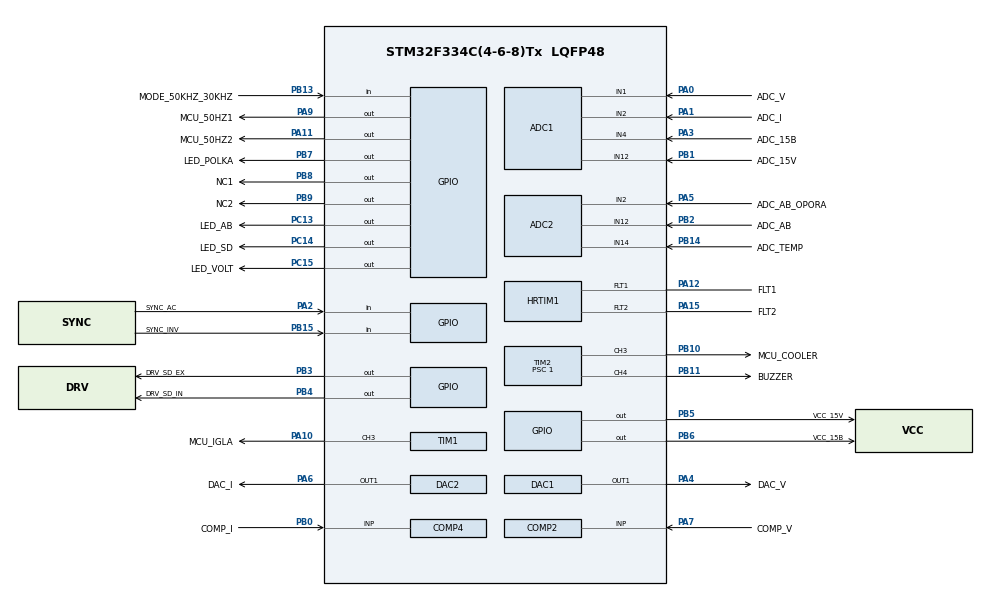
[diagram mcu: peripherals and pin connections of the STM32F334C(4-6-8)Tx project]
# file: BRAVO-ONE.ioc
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ADC1.AWD1HighThreshold=2500
ADC1.AWD1ITMode=ENABLE
ADC1.AWD1LowThreshold=1500
ADC1.Channel-3\#ChannelRegularConversion=ADC_CHANNEL_4
ADC1.Channel-4\#ChannelRegularConversion=ADC_CHANNEL_12
ADC1.ContinuousConvMode=ENABLE
ADC1.DMAContinuousRequests=ENABLE
ADC1.EOCSelection=ADC_EOC_SEQ_CONV
ADC1.EnableAnalogWatchDog1=true
ADC1.EnableRegularConversion=ENABLE
ADC1.ExternalTrigInjecConv=ADC_EXTERNALTRIGINJECCONV_HRTIM_TRG2
ADC1.ExternalTrigInjecConvEdge=ADC_EXTERNALTRIGINJECCONV_EDGE_RISINGFALLING
ADC1.InjNumberOfConversion=2
ADC1.InjectedChannel-1\#ChannelInjectedConversion=ADC_CHANNEL_1
ADC1.InjectedChannel-2\#ChannelInjectedConversion=ADC_CHANNEL_2
ADC1.InjectedConvMode=None
ADC1.InjectedOffset-1\#ChannelInjectedConversion=0
ADC1.InjectedOffset-2\#ChannelInjectedConversion=0
ADC1.InjectedOffsetNumber-1\#ChannelInjectedConversion=ADC_OFFSET_NONE
ADC1.InjectedOffsetNumber-2\#ChannelInjectedConversion=ADC_OFFSET_NONE
ADC1.InjectedRank-1\#ChannelInjectedConversion=1
ADC1.InjectedRank-2\#ChannelInjectedConversion=2
ADC1.InjectedSamplingTime-1\#ChannelInjectedConversion=ADC_SAMPLETIME_61CYCLES_5
ADC1.InjectedSamplingTime-2\#ChannelInjectedConversion=ADC_SAMPLETIME_61CYCLES_5
ADC1.NbrOfConversion=2
ADC1.NbrOfConversionFlag=1
ADC1.Offset-3\#ChannelRegularConversion=0
ADC1.Offset-4\#ChannelRegularConversion=0
ADC1.OffsetNumber-3\#ChannelRegularConversion=ADC_OFFSET_NONE
ADC1.OffsetNumber-4\#ChannelRegularConversion=ADC_OFFSET_NONE
ADC1.QueueInjectedContext=ENABLE
ADC1.Rank-3\#ChannelRegularConversion=1
ADC1.Rank-4\#ChannelRegularConversion=2
ADC1.SamplingTime-3\#ChannelRegularConversion=ADC_SAMPLETIME_601CYCLES_5
ADC1.SamplingTime-4\#ChannelRegularConversion=ADC_SAMPLETIME_601CYCLES_5
ADC1.WatchdogMode=ADC_ANALOGWATCHDOG_ALL_REG
ADC1.master=1
ADC2.AWD1HighThreshold=2500
ADC2.AWD1ITMode=ENABLE
ADC2.AWD1LowThreshold=1500
ADC2.Channel-0\#ChannelRegularConversion=ADC_CHANNEL_14
ADC2.Channel-1\#ChannelRegularConversion=ADC_CHANNEL_12
ADC2.Channel-2\#ChannelRegularConversion=ADC_CHANNEL_2
ADC2.ContinuousConvMode=ENABLE
ADC2.DMAContinuousRequests=ENABLE
ADC2.EOCSelection=ADC_EOC_SEQ_CONV
ADC2.EnableAnalogWatchDog1=true
ADC2.EnableInjectedConversion=DISABLE
ADC2.NbrOfConversion=3
ADC2.NbrOfConversionFlag=1
ADC2.Offset-0\#ChannelRegularConversion=0
ADC2.Offset-1\#ChannelRegularConversion=0
ADC2.Offset-2\#ChannelRegularConversion=0
ADC2.OffsetNumber-0\#ChannelRegularConversion=ADC_OFFSET_NONE
ADC2.OffsetNumber-1\#ChannelRegularConversion=ADC_OFFSET_NONE
ADC2.OffsetNumber-2\#ChannelRegularConversion=ADC_OFFSET_NONE
ADC2.Rank-0\#ChannelRegularConversion=1
ADC2.Rank-1\#ChannelRegularConversion=2
ADC2.Rank-2\#ChannelRegularConversion=3
ADC2.SamplingTime-0\#ChannelRegularConversion=ADC_SAMPLETIME_601CYCLES_5
ADC2.SamplingTime-1\#ChannelRegularConversion=ADC_SAMPLETIME_601CYCLES_5
ADC2.SamplingTime-2\#ChannelRegularConversion=ADC_SAMPLETIME_601CYCLES_5
ADC2.WatchdogChannel=ADC_CHANNEL_12
COMP2.InvertingInput=COMP_INVERTINGINPUT_DAC1_CH1
COMP2.TriggerMode=COMP_TRIGGERMODE_IT_RISING_FALLING
COMP4.InvertingInput=COMP_INVERTINGINPUT_DAC2_CH1
COMP4.TriggerMode=COMP_TRIGGERMODE_IT_RISING_FALLING
DAC1.DAC_Trigger=DAC_TRIGGER_HRTIM1_DACTRG1
DAC1.TriangleAmplitude=DAC_TRIANGLEAMPLITUDE_4095
DAC1.WaveGeneration=TriangleWaveGeneration
DAC2.DAC_Trigger=DAC_TRIGGER_HRTIM1_DACTRG3
Dma.ADC1.0.Direction=DMA_PERIPH_TO_MEMORY
Dma.ADC1.0.Instance=DMA1_Channel1
Dma.ADC1.0.MemDataAlignment=DMA_MDATAALIGN_HALFWORD
Dma.ADC1.0.MemInc=DMA_MINC_ENABLE
Dma.ADC1.0.Mode=DMA_CIRCULAR
Dma.ADC1.0.PeriphDataAlignment=DMA_PDATAALIGN_HALFWORD
Dma.ADC1.0.PeriphInc=DMA_PINC_DISABLE
Dma.ADC1.0.Priority=DMA_PRIORITY_MEDIUM
Dma.ADC2.1.Direction=DMA_PERIPH_TO_MEMORY
Dma.ADC2.1.Instance=DMA1_Channel4
Dma.ADC2.1.MemDataAlignment=DMA_MDATAALIGN_HALFWORD
Dma.ADC2.1.MemInc=DMA_MINC_ENABLE
Dma.ADC2.1.Mode=DMA_CIRCULAR
Dma.ADC2.1.PeriphDataAlignment=DMA_PDATAALIGN_HALFWORD
Dma.ADC2.1.PeriphInc=DMA_PINC_DISABLE
Dma.ADC2.1.Priority=DMA_PRIORITY_LOW
Dma.DAC1_CH1.2.Direction=DMA_MEMORY_TO_PERIPH
Dma.DAC1_CH1.2.Instance=DMA1_Channel3
Dma.DAC1_CH1.2.MemDataAlignment=DMA_MDATAALIGN_HALFWORD
Dma.DAC1_CH1.2.MemInc=DMA_MINC_ENABLE
Dma.DAC1_CH1.2.Mode=DMA_CIRCULAR
Dma.DAC1_CH1.2.PeriphDataAlignment=DMA_PDATAALIGN_HALFWORD
Dma.DAC1_CH1.2.PeriphInc=DMA_PINC_DISABLE
Dma.DAC1_CH1.2.Priority=DMA_PRIORITY_VERY_HIGH
Dma.DAC2_CH1.3.Direction=DMA_MEMORY_TO_PERIPH
Dma.DAC2_CH1.3.Instance=DMA1_Channel5
Dma.DAC2_CH1.3.MemDataAlignment=DMA_MDATAALIGN_HALFWORD
Dma.DAC2_CH1.3.MemInc=DMA_MINC_ENABLE
Dma.DAC2_CH1.3.Mode=DMA_CIRCULAR
Dma.DAC2_CH1.3.PeriphDataAlignment=DMA_PDATAALIGN_HALFWORD
Dma.DAC2_CH1.3.PeriphInc=DMA_PINC_DISABLE
Dma.DAC2_CH1.3.Priority=DMA_PRIORITY_HIGH
Dma.Request0=ADC1
Dma.Request1=ADC2
Dma.Request2=DAC1_CH1
Dma.Request3=DAC2_CH1
HRTIM1.ADCTrigger2_Source1=HRTIM_ADCTRIGGEREVENT24_MASTER_CMP2
HRTIM1.ADCTrigger2_Source2=HRTIM_ADCTRIGGEREVENT24_MASTER_CMP4
HRTIM1.ADCTrigger_Id1=__NULL
HRTIM1.ADCTrigger_Id2=HRTIM_ADCTRIGGER_2
HRTIM1.BurstDMAconfig-MasterTimer=__NULL
HRTIM1.CompareUnit1-MasterTimer=HRTIM_COMPAREUNIT_1
HRTIM1.CompareUnit2-MasterTimer=HRTIM_COMPAREUNIT_2
HRTIM1.CompareUnit3-MasterTimer=HRTIM_COMPAREUNIT_3
HRTIM1.CompareUnit4-MasterTimer=HRTIM_COMPAREUNIT_4
HRTIM1.CompareValue1-MasterTimer=3400
HRTIM1.CompareValue2-MasterTimer=10200
HRTIM1.CompareValue3-MasterTimer=28400
HRTIM1.CompareValue4-MasterTimer=35200
HRTIM1.DACSynchro-MasterTimer=HRTIM_DACSYNC_NONE
HRTIM1.Enable=HRTIM_BURSTMODECTL_DISABLED
HRTIM1.Event_EEV1=HRTIM_EVENT_1
HRTIM1.Event_EEV2=HRTIM_EVENT_2
HRTIM1.Event_EEV3=__NULL
HRTIM1.Event_EEV4=__NULL
HRTIM1.Event_EEV5=__NULL
HRTIM1.Event_EEV6=__NULL
HRTIM1.Event_EEV7=__NULL
HRTIM1.FastMode_EEV1=HRTIM_EVENTFASTMODE_ENABLE
HRTIM1.FastMode_EEV2=HRTIM_EVENTFASTMODE_ENABLE
HRTIM1.FaultEnable_Source1-No_output_TE=HRTIM_TIMFAULTENABLE_FAULT1
HRTIM1.FaultEnable_Source2-No_output_TE=HRTIM_TIMFAULTENABLE_FAULT2
HRTIM1.Filter_FaultLine1=HRTIM_FAULTFILTER_15
HRTIM1.Filter_FaultLine2=HRTIM_FAULTFILTER_15
HRTIM1.HRTIMInterruptResquests1=HRTIM_IT_FLT1
HRTIM1.HRTIMInterruptResquests2=HRTIM_IT_FLT2
HRTIM1.HRTIMInterruptResquests3=HRTIM_IT_SYSFLT
HRTIM1.InterruptRequests1-No_output_TE=HRTIM_TIM_IT_REP
HRTIM1.InterruptRequests1_Master=HRTIM_MASTER_IT_MREP
HRTIM1.ModeTimeBase-No_output_TE=HRTIM_MODE_SINGLESHOT_RETRIGGERABLE
HRTIM1.NumberADCTriggerSource2=2
HRTIM1.NumberDMARequests_Master=0
HRTIM1.NumberFaultEnable-No_output_TE=2
HRTIM1.NumberInterruptRequests-No_output_TE=1
HRTIM1.NumberInterruptRequests_Master-MasterTimer=1
HRTIM1.NumberResetTrigger-No_output_TE=1
HRTIM1.NumberUpdateTrigger-No_output_TE=1
HRTIM1.Periode_MASTER=50000
HRTIM1.Periode_TE=50000
HRTIM1.PreloadEnable-MasterTimer=HRTIM_PRELOAD_ENABLED
HRTIM1.PreloadEnable-No_output_TE=HRTIM_PRELOAD_ENABLED
HRTIM1.PrescalerRatio_MASTER=HRTIM_PRESCALERRATIO_MUL16
HRTIM1.PrescalerRatio_TE=HRTIM_PRESCALERRATIO_MUL16
HRTIM1.RepetitionCounter-MasterTimer=230
HRTIM1.RepetitionCounter-No_output_TE=227
HRTIM1.RepetitionUpdate-MasterTimer=HRTIM_UPDATEONREPETITION_ENABLED
HRTIM1.ResetTrigger1-No_output_TE=HRTIM_TIMRESETTRIGGER_UPDATE
HRTIM1.Source_EEV1=HRTIM_EVENTSRC_2
HRTIM1.UpdateTrigger1-No_output_TE=HRTIM_TIMUPDATETRIGGER_MASTER
IWDG.Prescaler=IWDG_PRESCALER_256
Mcu.Family=STM32F3
Mcu.Name=STM32F334C(4-6-8)Tx
Mcu.Package=LQFP48
NVIC.ADC1_2_IRQn=true\:0\:2\:true\:false\:true\:true\:true
NVIC.COMP2_IRQn=true\:0\:0\:false\:false\:true\:false\:true
NVIC.COMP4_6_IRQn=true\:0\:0\:false\:false\:true\:false\:true
NVIC.DMA1_Channel1_IRQn=true\:0\:1\:true\:false\:true\:false\:true
NVIC.DMA1_Channel3_IRQn=true\:0\:1\:true\:false\:true\:false\:true
NVIC.DMA1_Channel4_IRQn=true\:0\:1\:true\:false\:true\:false\:true
NVIC.DMA1_Channel5_IRQn=true\:0\:1\:true\:false\:true\:false\:true
NVIC.HRTIM1_FLT_IRQn=true\:0\:0\:false\:false\:true\:true\:true
NVIC.HRTIM1_Master_IRQn=true\:0\:0\:false\:false\:true\:true\:true
NVIC.HRTIM1_TIME_IRQn=true\:0\:0\:false\:false\:true\:true\:true
NVIC.PVD_IRQn=true\:0\:2\:true\:false\:true\:true\:true
NVIC.PriorityGroup=NVIC_PRIORITYGROUP_2
NVIC.TIM1_BRK_TIM15_IRQn=true\:3\:0\:true\:false\:true\:true\:true
NVIC.TIM1_TRG_COM_TIM17_IRQn=true\:3\:0\:true\:false\:true\:true\:true
NVIC.TIM1_UP_TIM16_IRQn=true\:3\:0\:true\:false\:true\:true\:true
NVIC.TIM3_IRQn=true\:3\:0\:true\:false\:true\:true\:true
NVIC.TIM6_DAC1_IRQn=true\:3\:0\:true\:false\:true\:true\:true
NVIC.TIM7_DAC2_IRQn=true\:3\:0\:true\:false\:true\:true\:true
PA0.GPIO_Label=ADC_V
PA0.Mode=IN1-Single-Ended
PA0.Signal=ADC1_IN1
PA1.GPIO_Label=ADC_I
PA1.Mode=IN2-Single-Ended
PA1.Signal=ADC1_IN2
PA10.GPIO_Label=MCU_IGLA
PA10.GPIO_Speed=GPIO_SPEED_FREQ_HIGH
PA10.Signal=S_TIM1_CH3
PA11.GPIO_Label=MCU_50HZ2
PA11.GPIO_Speed=GPIO_SPEED_FREQ_HIGH
PA11.Signal=GPIO_Output
PA12.GPIO_Label=FLT1
PA12.GPIO_Speed=GPIO_SPEED_FREQ_HIGH
PA12.Mode=Fault_Enable1
PA12.Signal=HRTIM1_FLT1
PA13.GPIO_Label=DIO
PA13.Mode=Serial_Wire
PA13.Signal=SYS_JTMS-SWDIO
PA14.GPIO_Label=CLK
PA14.Mode=Serial_Wire
PA14.Signal=SYS_JTCK-SWCLK
PA15.GPIO_Label=FLT2
PA15.GPIO_Speed=GPIO_SPEED_FREQ_HIGH
PA15.Mode=Fault_Enable2
PA15.Signal=HRTIM1_FLT2
PA2.GPIO_Label=SYNC_AC
PA2.Signal=GPIO_Input
PA3.GPIO_Label=ADC_15B
PA3.Mode=IN4-Single-Ended
PA3.Signal=ADC1_IN4
PA4.GPIO_Label=DAC_V
PA4.Signal=COMP_DAC11_group
PA5.GPIO_Label=ADC_AB_OPORA
PA5.Mode=IN2-Single-Ended
PA5.Signal=ADC2_IN2
PA6.GPIO_Label=DAC_I
PA6.Signal=COMP_DAC21_group
PA7.GPIO_Label=COMP_V
PA7.Mode=INP
PA7.Signal=COMP2_INP
PA8.GPIO_Label=IN1
PA8.Signal=HRTIM1_CHA1
PA9.GPIO_Label=MCU_50HZ1
PA9.GPIO_Speed=GPIO_SPEED_FREQ_HIGH
PA9.Signal=GPIO_Output
PB0.GPIO_Label=COMP_I
PB0.Mode=INP
PB0.Signal=COMP4_INP
PB1.GPIO_Label=ADC_15V
PB1.Mode=IN12-Single-Ended
PB1.Signal=ADC1_IN12
PB10.GPIO_Label=MCU_COOLER
PB10.GPIO_Speed=GPIO_SPEED_FREQ_HIGH
PB10.Signal=S_TIM2_CH3
PB11.GPIO_Label=BUZZER
PB11.GPIO_Speed=GPIO_SPEED_FREQ_HIGH
PB11.Signal=S_TIM2_CH4
PB12.GPIO_Label=IN2
PB12.Signal=HRTIM1_CHC1
PB13.GPIO_Label=MODE_50KHZ_30KHZ
PB13.Signal=GPIO_Input
PB14.GPIO_Label=ADC_TEMP
PB14.Mode=IN14-Single-Ended
PB14.Signal=ADC2_IN14
PB15.GPIO_Label=SYNC_INV
PB15.Signal=GPIO_Input
PB2.GPIO_Label=ADC_AB
PB2.Mode=IN12-Single-Ended
PB2.Signal=ADC2_IN12
PB3.GPIO_Label=DRV_SD_EX
PB3.GPIO_Speed=GPIO_SPEED_FREQ_HIGH
PB3.Signal=GPIO_Output
PB4.GPIO_Label=DRV_SD_IN
PB4.GPIO_Speed=GPIO_SPEED_FREQ_HIGH
PB4.PinState=GPIO_PIN_SET
PB4.Signal=GPIO_Output
PB5.GPIO_Label=VCC_15V
PB5.GPIO_Speed=GPIO_SPEED_FREQ_HIGH
PB5.Signal=GPIO_Output
PB6.GPIO_FM6=SYSCFG_CFGR1_I2C_PB6_FMP
PB6.GPIO_Label=VCC_15B
PB6.GPIO_Speed=GPIO_SPEED_FREQ_HIGH
PB6.Signal=GPIO_Output
PB7.GPIO_FM7=SYSCFG_CFGR1_I2C_PB7_FMP
PB7.GPIO_Label=LED_POLKA
PB7.GPIO_Speed=GPIO_SPEED_FREQ_HIGH
PB7.PinState=GPIO_PIN_SET
PB7.Signal=GPIO_Output
PB8.GPIO_Label=NC1
PB8.Signal=GPIO_Output
PB9.GPIO_Label=NC2
PB9.Signal=GPIO_Output
PC13.GPIO_Label=LED_AB
PC13.GPIO_Speed=GPIO_SPEED_FREQ_LOW
PC13.PinState=GPIO_PIN_SET
PC13.Signal=GPIO_Output
PC14\ /\ OSC32_IN.GPIO_Label=LED_SD
PC14\ /\ OSC32_IN.GPIO_Speed=GPIO_SPEED_FREQ_HIGH
PC14\ /\ OSC32_IN.PinState=GPIO_PIN_SET
PC14\ /\ OSC32_IN.Signal=GPIO_Output
PC15\ /\ OSC32_OUT.GPIO_Label=LED_VOLT
PC15\ /\ OSC32_OUT.GPIO_Speed=GPIO_SPEED_FREQ_HIGH
PC15\ /\ OSC32_OUT.PinState=GPIO_PIN_SET
PC15\ /\ OSC32_OUT.Signal=GPIO_Output
PF0\ /\ OSC_IN.GPIO_Label=OSC_IN
PF0\ /\ OSC_IN.Mode=HSE-External-Oscillator
PF0\ /\ OSC_IN.Signal=RCC_OSC_IN
PF1\ /\ OSC_OUT.GPIO_Label=OSC_OUT
PF1\ /\ OSC_OUT.Mode=HSE-External-Oscillator
PF1\ /\ OSC_OUT.Signal=RCC_OSC_OUT
ProjectManager.HeapSize=0x200
ProjectManager.StackSize=0x400
ProjectManager.TargetToolchain=STM32CubeIDE
RCC.AHBFreq_Value=72000000
RCC.APB1CLKDivider=RCC_HCLK_DIV2
RCC.APB1Freq_Value=36000000
RCC.APB1TimFreq_Value=72000000
RCC.APB2Freq_Value=72000000
RCC.APB2TimFreq_Value=72000000
RCC.CortexFreq_Value=72000000
RCC.HCLKFreq_Value=72000000
RCC.HRTIMSelection=RCC_HRTIM1CLK_PLLCLK
RCC.HSE_VALUE=12000000
RCC.HSI_VALUE=8000000
RCC.LSE_VALUE=32768
RCC.PLLMUL=RCC_PLL_MUL6
RCC.PLLSourceVirtual=RCC_PLLSOURCE_HSE
RCC.SYSCLKFreq_VALUE=72000000
RCC.SYSCLKSourceVirtual=RCC_SYSCLKSOURCE_PLLCLK
RCC.TIM1Selection=RCC_TIM1CLK_PLLCLK
SH.COMP_DAC11_group.0=DAC1_OUT1,DAC_OUT1
SH.COMP_DAC21_group.0=DAC2_OUT1,Switch_Enable_OUT1
SH.S_TIM1_CH3.0=TIM1_CH3,PWM Generation3 CH3
SH.S_TIM2_CH3.0=TIM2_CH3,PWM Generation3 CH3
SH.S_TIM2_CH4.0=TIM2_CH4,PWM Generation4 CH4
TIM1.AutoReloadPreload=TIM_AUTORELOAD_PRELOAD_ENABLE
TIM1.Channel-PWM\ Generation3\ CH3=TIM_CHANNEL_3
TIM1.OCFastMode_PWM-PWM\ Generation3\ CH3=TIM_OCFAST_ENABLE
TIM1.Period=28799
TIM15.AutoReloadPreload=TIM_AUTORELOAD_PRELOAD_ENABLE
TIM15.ClockDivision=TIM_CLOCKDIVISION_DIV4
TIM15.Period=63999
TIM15.Prescaler=33749
TIM15.RepetitionCounter=8
TIM16.AutoReloadPreload=TIM_AUTORELOAD_PRELOAD_ENABLE
TIM16.ClockDivision=TIM_CLOCKDIVISION_DIV4
TIM16.Period=63999
TIM16.Prescaler=33749
TIM16.RepetitionCounter=0
TIM17.AutoReloadPreload=TIM_AUTORELOAD_PRELOAD_ENABLE
TIM17.ClockDivision=TIM_CLOCKDIVISION_DIV4
TIM17.Period=63999
TIM17.Prescaler=33749
TIM17.RepetitionCounter=2
TIM2.AutoReloadPreload=TIM_AUTORELOAD_PRELOAD_ENABLE
TIM2.Channel-PWM\ Generation3\ CH3=TIM_CHANNEL_3
TIM2.Channel-PWM\ Generation4\ CH4=TIM_CHANNEL_4
TIM2.ClockDivision=TIM_CLOCKDIVISION_DIV1
TIM2.OCFastMode_PWM-PWM\ Generation3\ CH3=TIM_OCFAST_ENABLE
TIM2.OCFastMode_PWM-PWM\ Generation4\ CH4=TIM_OCFAST_ENABLE
TIM2.Period=35999
TIM2.Prescaler=1
TIM3.AutoReloadPreload=TIM_AUTORELOAD_PRELOAD_ENABLE
TIM3.Period=63999
TIM3.Prescaler=3374
TIM6.AutoReloadPreload=TIM_AUTORELOAD_PRELOAD_ENABLE
TIM6.Period=63999
TIM6.Prescaler=1124
TIM7.AutoReloadPreload=TIM_AUTORELOAD_PRELOAD_ENABLE
TIM7.Period=63999
TIM7.Prescaler=1124
VP_COMP2_VS_DAC1OUT1.Mode=INM_DAC1OUT1
VP_COMP4_VS_DAC2OUT1.Mode=INM_DAC2OUT1
VP_HRTIM1_VS_hrtimMasterTimerNoOutput.Mode=MasterTimer
VP_HRTIM1_VS_hrtimTimerENoOutput.Mode=No_output_TE
VP_IWDG_VS_IWDG.Mode=IWDG_Activate
VP_TIM15_VS_ClockSourceINT.Mode=Internal
VP_TIM16_VS_ClockSourceINT.Mode=Enable_Timer
VP_TIM17_VS_ClockSourceINT.Mode=Enable_Timer
VP_TIM1_VS_ClockSourceINT.Mode=Internal
VP_TIM2_VS_ClockSourceINT.Mode=Internal
VP_TIM3_VS_ClockSourceINT.Mode=Internal
VP_TIM6_VS_ClockSourceINT.Mode=Enable_Timer
VP_TIM7_VS_ClockSourceINT.Mode=Enable_Timer
board=custom

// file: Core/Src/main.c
/* USER CODE BEGIN Header */
/**
  ******************************************************************************
  * @file           : main.c
  * @brief          : Main program body
  ******************************************************************************
  * @attention
  *
  * <h2><center>&copy; Copyright (c) 2020 STMicroelectronics.
  * All rights reserved.</center></h2>
  *
  * This software component is licensed by ST under BSD 3-Clause license,
  * the "License"; You may not use this file except in compliance with the
  * License. You may obtain a copy of the License at:
  *                        opensource.org/licenses/BSD-3-Clause
  *
  ******************************************************************************
  */
/* USER CODE END Header */

#include "main.h"
#include "adc.h"
#include "comp.h"
#include "dac.h"
#include "dma.h"
#include "hrtim.h"
#include "iwdg.h"
#include "tim.h"
#include "gpio.h"

/* USER CODE BEGIN Includes */
#include "bravogl.h"
/* USER CODE END Includes */

void SystemClock_Config(void);

int main(void)
{

  /* MCU Configuration--------------------------------------------------------*/

  /* Reset of all peripherals, Initializes the Flash interface and the Systick. */

  LL_APB2_GRP1_EnableClock(LL_APB2_GRP1_PERIPH_SYSCFG);
  LL_APB1_GRP1_EnableClock(LL_APB1_GRP1_PERIPH_PWR);

  NVIC_SetPriorityGrouping(NVIC_PRIORITYGROUP_2);

  /* System interrupt init*/
  /* SysTick_IRQn interrupt configuration */
  NVIC_SetPriority(SysTick_IRQn, NVIC_EncodePriority(NVIC_GetPriorityGrouping(),0, 3));

  /* Peripheral interrupt init*/
  /* PVD_IRQn interrupt configuration */
  NVIC_SetPriority(PVD_IRQn, NVIC_EncodePriority(NVIC_GetPriorityGrouping(),0, 2));
  NVIC_EnableIRQ(PVD_IRQn);

  /* Configure the system clock */
  SystemClock_Config();

  /* USER CODE BEGIN SysInit */

  /* Enable the peripheral clock of DBG register (uncomment for debug purpose) */
  /* ------------------------------------------------------------------------- */
	#ifdef BRAVO_DEBUG
	  LL_DBGMCU_APB1_GRP1_FreezePeriph(LL_DBGMCU_APB1_GRP1_IWDG_STOP);
	#endif

  /* USER CODE END SysInit */

  /* Initialize all configured peripherals */
  MX_GPIO_Init();
  MX_DMA_Init();
  MX_IWDG_Init();
  MX_ADC1_Init();
  MX_COMP2_Init();
  MX_COMP4_Init();
  MX_DAC1_Init();
  MX_DAC2_Init();
  MX_TIM1_Init();
  MX_TIM2_Init();
  MX_TIM16_Init();
  MX_TIM17_Init();
  MX_ADC2_Init();
  MX_HRTIM1_Init();
  MX_TIM3_Init();
  MX_TIM6_Init();
  MX_TIM7_Init();
  MX_TIM15_Init();
  /* USER CODE BEGIN 2 */

  BRAVO_Init();

  /* USER CODE END 2 */

  /* Infinite loop */
  /* USER CODE BEGIN WHILE */
  while (1)
  {

	  LL_IWDG_ReloadCounter(IWDG); // Reset IWDG

    /* USER CODE END WHILE */

  }
}

void SystemClock_Config(void)
{
  LL_FLASH_SetLatency(LL_FLASH_LATENCY_2);

   if(LL_FLASH_GetLatency() != LL_FLASH_LATENCY_2)
  {
  Error_Handler();
  }
  LL_RCC_HSE_Enable();

   /* Wait till HSE is ready */
  while(LL_RCC_HSE_IsReady() != 1)
  {

  }
  LL_RCC_LSI_Enable();

   /* Wait till LSI is ready */
  while(LL_RCC_LSI_IsReady() != 1)
  {

  }
  LL_RCC_PLL_ConfigDomain_SYS(LL_RCC_PLLSOURCE_HSE_DIV_1, LL_RCC_PLL_MUL_6);
  LL_RCC_PLL_Enable();

   /* Wait till PLL is ready */
  while(LL_RCC_PLL_IsReady() != 1)
  {

  }
  LL_RCC_SetAHBPrescaler(LL_RCC_SYSCLK_DIV_1);
  LL_RCC_SetAPB1Prescaler(LL_RCC_APB1_DIV_2);
  LL_RCC_SetAPB2Prescaler(LL_RCC_APB1_DIV_1);
  LL_RCC_SetSysClkSource(LL_RCC_SYS_CLKSOURCE_PLL);

   /* Wait till System clock is ready */
  while(LL_RCC_GetSysClkSource() != LL_RCC_SYS_CLKSOURCE_STATUS_PLL)
  {

  }
  LL_Init1msTick(72000000);
  LL_SetSystemCoreClock(72000000);
  LL_RCC_SetTIMClockSource(LL_RCC_TIM1_CLKSOURCE_PLL);
  LL_RCC_SetHRTIMClockSource(RCC_CFGR3_HRTIM1SW_PLL);
  LL_RCC_SetADCClockSource(LL_RCC_ADC12_CLKSRC_PLL_DIV_1);
}

void Error_Handler(void)
{
}

/************************ (C) COPYRIGHT STMicroelectronics *****END OF FILE****/
